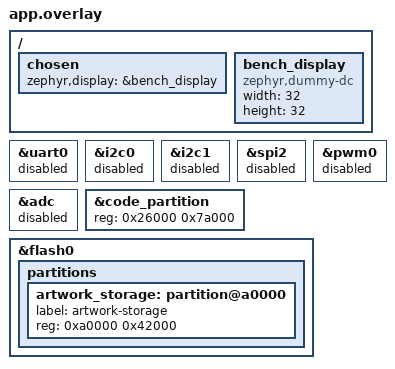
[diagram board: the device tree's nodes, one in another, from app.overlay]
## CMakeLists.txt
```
# SPDX-License-Identifier: MIT
cmake_minimum_required(VERSION 3.20.0)
get_filename_component(BADGE_REPOSITORY_ROOT "${CMAKE_CURRENT_SOURCE_DIR}/../../.." ABSOLUTE)
get_filename_component(BADGE_COMMON_DIR "${CMAKE_CURRENT_SOURCE_DIR}/../../common" ABSOLUTE)
list(APPEND ZEPHYR_EXTRA_MODULES ${BADGE_COMMON_DIR}/src/drivers)
set(BADGE_MAIN_SOURCE ${CMAKE_CURRENT_SOURCE_DIR}/src/main.cpp)
find_package(Zephyr REQUIRED HINTS $ENV{ZEPHYR_BASE})
project(promicro_badge_bench LANGUAGES C CXX)
include(${BADGE_COMMON_DIR}/application.cmake)
```

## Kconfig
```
# SPDX-License-Identifier: MIT
rsource "../../common/Kconfig"
config BADGE_USB_BENCH
    bool "Headless Pro Micro BLE/settings bench with USB pairing display"
    depends on BOARD_PROMICRO_NRF52840 && APP_BLE && !APP_AUDIO && !APP_MOTION
source "Kconfig.zephyr"
```

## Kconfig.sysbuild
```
# SPDX-License-Identifier: MIT
# Keep the factory UF2 bootloader; do not add MCUboot or repartition with PM.
choice BOOTLOADER
    default BOOTLOADER_NONE
endchoice
config PARTITION_MANAGER
    default n
source "share/sysbuild/Kconfig"
```

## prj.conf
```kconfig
# SPDX-License-Identifier: MIT
CONFIG_CPP=y
CONFIG_STD_CPP17=y
CONFIG_CPP_EXCEPTIONS=n
CONFIG_CPP_RTTI=n
CONFIG_MAIN_STACK_SIZE=16384
CONFIG_LOG=y
CONFIG_USE_SEGGER_RTT=y
CONFIG_LOG_BACKEND_RTT=y
CONFIG_LOG_BACKEND_UART=n
CONFIG_LOG_PRINTK=n
CONFIG_UART_CONSOLE=n
CONFIG_SERIAL=y
CONFIG_UART_LINE_CTRL=y
CONFIG_DISPLAY=y
CONFIG_DUMMY_DISPLAY=y
CONFIG_I2C=y
CONFIG_APP_PROTOTYPE=y
CONFIG_APP_NFC=y
CONFIG_APP_BLE=y
CONFIG_APP_AUDIO=n
CONFIG_APP_MOTION=n
CONFIG_APP_BRINGUP_CHECKS=n
CONFIG_BADGE_USB_BENCH=y
CONFIG_BT=y
CONFIG_BT_PERIPHERAL=y
CONFIG_BT_SMP=y
CONFIG_BT_SETTINGS=y
CONFIG_BT_SMP_SC_ONLY=y
CONFIG_BT_SMP_ENFORCE_MITM=y
CONFIG_BT_SMP_APP_PAIRING_ACCEPT=y
CONFIG_BT_MAX_CONN=1
CONFIG_BT_MAX_PAIRED=1
CONFIG_BT_DEVICE_NAME="Pixel Badge Bench"
CONFIG_BT_RX_STACK_SIZE=4096
CONFIG_SYSTEM_WORKQUEUE_STACK_SIZE=2048
CONFIG_BT_L2CAP_TX_MTU=247
CONFIG_BT_BUF_ACL_RX_SIZE=251
CONFIG_BT_BUF_ACL_TX_SIZE=251
CONFIG_BT_BUF_ACL_TX_COUNT=4
CONFIG_BT_CONN_TX_MAX=4
```

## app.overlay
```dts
/* SPDX-License-Identifier: MIT */
/ {
    chosen { zephyr,display = &bench_display; };
    bench_display: bench_display {
        compatible = "zephyr,dummy-dc";
        width = <32>;
        height = <32>;
    };
};
/* No external peripherals or GPIO outputs on an unidentified clone. */
&uart0 { status = "disabled"; };
&i2c0 { status = "disabled"; };
&i2c1 { status = "disabled"; };
&spi2 { status = "disabled"; };
&pwm0 { status = "disabled"; };
&adc { status = "disabled"; };
/* Preserve the UF2/MBR/SoftDevice regions. This candidate uses SDK SDv6 offsets;
 * compare INFO_UF2 before deployment. These are bench-only asset locations. */
&code_partition { reg = <0x26000 0x7a000>; };
&flash0 {
    partitions {
        artwork_storage: partition@a0000 {
            label = "artwork-storage";
            reg = <0xa0000 0x42000>;
        };
    };
};
```

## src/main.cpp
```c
/* SPDX-License-Identifier: MIT */
#include "badge/ble.hpp"
#include "badge/modes.hpp"
#include "badge/nfc.hpp"
#include "badge/settings_store.hpp"
#include <zephyr/device.h>
#include <zephyr/drivers/uart.h>
#include <zephyr/kernel.h>
#include <zephyr/sys/crc.h>
#include <zephyr/sys/util.h>
#include <errno.h>
#include <stdio.h>
#include <string.h>

BUILD_ASSERT(IS_ENABLED(CONFIG_BADGE_USB_BENCH));
BUILD_ASSERT(!IS_ENABLED(CONFIG_APP_AUDIO) && !IS_ENABLED(CONFIG_APP_MOTION));
namespace
{
const device *const usb = DEVICE_DT_GET(DT_CHOSEN(zephyr_console));
badge::SettingsService settings, candidate;
badge::Modes modes;
badge::Frame frame;
int load_result;
uint32_t rendered;
void reply(const char *text)
{
	/* Direct USB output only. Codes are not RTT/log messages or saved records. */
	while (*text) {
		uart_poll_out(usb, *text++);
	}
}
int apply(void *, const badge::ConfigCommand &command)
{
	candidate = settings;
	if (!candidate.load(command.field, command.value(), command.length)) {
		return -EINVAL;
	}
	const badge::Mode previous = modes.active();
	if (!modes.configure(candidate.values()) ||
	    (command.field == badge::Field::kDefaultMode &&
	     !modes.select(candidate.values().default_mode, k_uptime_get_32()))) {
		(void)modes.configure(settings.values());
		(void)modes.select(previous, k_uptime_get_32());
		return -EINVAL;
	}
	modes.render(frame, k_uptime_get_32());
	const int rc = settings.save(command.field, command.value(), command.length,
				     badge::store_field, nullptr);
	if (rc != 0) {
		(void)modes.configure(settings.values());
		(void)modes.select(previous, k_uptime_get_32());
	}
	return rc;
}
void command(unsigned char key)
{
	if (key == 'p') {
		badge::open_ble_pairing();
		reply("Pairing window requested (60s). Connect Pixel Badge, then type k.\r\n");
	} else if (key == 'k') {
		uint32_t code = 0;
		char line[96];
		if (badge::ble_bench_passkey(code)) {
			snprintf(line, sizeof(line), "Pairing code: %06u\r\n", code);
			reply(line);
			memset(line, 0, sizeof(line));
			code = 0;
		} else {
			reply("No current pairing code. Type p and connect the app first.\r\n");
		}
	} else if (key == 's') {
		char line[160];
		const uint32_t checksum = frame.grayscale
						  ? crc32_ieee(frame.levels, sizeof(frame.levels))
						  : crc32_ieee(frame.bytes, sizeof(frame.bytes));
		snprintf(line, sizeof(line),
			 "BENCH uptime=%u load=%d frames=%u frame_crc=%08x mode=%u brightness=%u "
			 "NFC=%d\r\n",
			 k_uptime_get_32(), load_result, rendered, checksum,
			 static_cast<unsigned>(modes.active()), settings.values().brightness,
			 badge::nfc_last_result());
		reply(line);
	} else if (key == 'h') {
		reply("Pixel Badge headless bench: p=pair, k=show code, s=status, h=help.\r\n"
		      "No matrix, IMU, microphone or NFC tag. No recording.\r\n");
	}
}
} // namespace
int main()
{
	load_result = badge::load_settings(settings, false);
	modes.start(settings.values(), load_result != 0);
	badge::start_nfc(settings.values().url, load_result == 0);
	badge::start_ble();
	while (true) {
		badge::poll_ble(settings.values(), modes, load_result == 0, load_result == 0, apply,
				nullptr);
		// Exercise the actual renderer and URL rollback state without physical IO.
		if (badge::poll_nfc(settings, modes)) {
			modes.render(frame, k_uptime_get_32());
			badge::nfc_display_result(0); // RAM rendering only; never a hardware pass.
		}
		modes.render(frame, k_uptime_get_32());
		++rendered;
		uint32_t dtr = 0;
		if (device_is_ready(usb) &&
		    uart_line_ctrl_get(usb, UART_LINE_CTRL_DTR, &dtr) == 0 && dtr) {
			unsigned char key;
			// Bound USB work so a host input flood cannot starve BLE/main ownership.
			for (unsigned i = 0; i < 16 && uart_poll_in(usb, &key) == 0; ++i) {
				command(key);
			}
		}
		k_msleep(20);
	}
}
```
